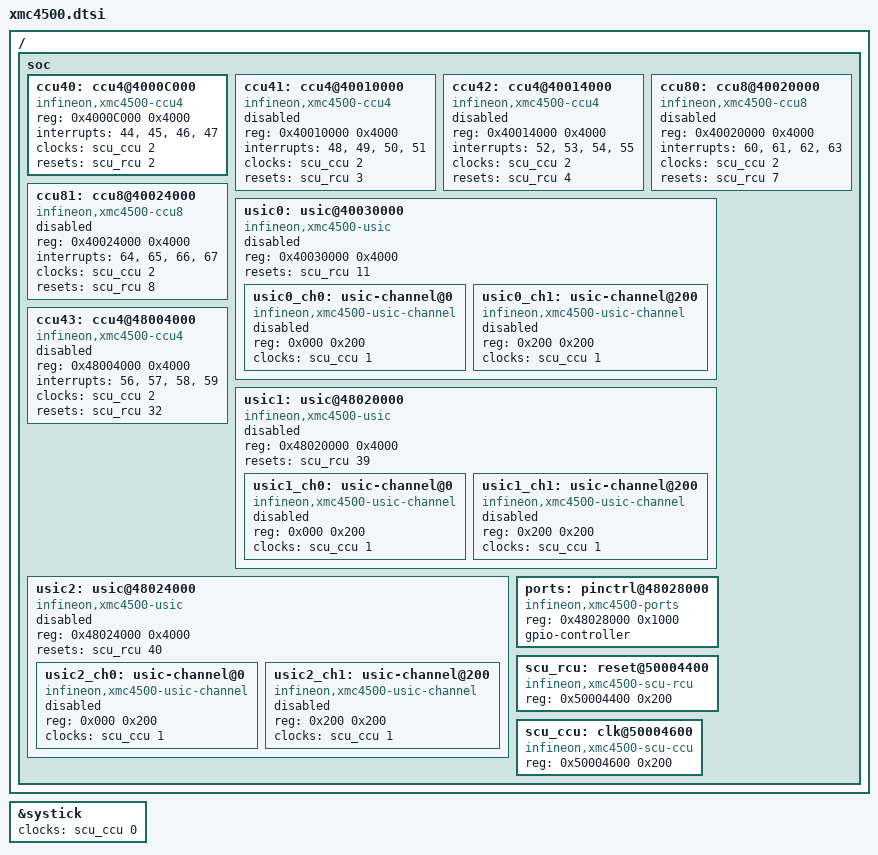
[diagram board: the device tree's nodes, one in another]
/*
 * Device tree for Infineon XMC4500
 *
 * Copyright 2015-2016 Andreas Färber
 *
 * This file is dual-licensed: you can use it either under the terms
 * of the GPL or the X11 license, at your option. Note that this dual
 * licensing only applies to this file, and not this project as a
 * whole.
 *
 *  a) This file is free software; you can redistribute it and/or
 *     modify it under the terms of the GNU General Public License as
 *     published by the Free Software Foundation; either version 2 of the
 *     License, or (at your option) any later version.
 *
 *     This file is distributed in the hope that it will be useful,
 *     but WITHOUT ANY WARRANTY; without even the implied warranty of
 *     MERCHANTABILITY or FITNESS FOR A PARTICULAR PURPOSE.  See the
 *     GNU General Public License for more details.
 *
 * Or, alternatively,
 *
 *  b) Permission is hereby granted, free of charge, to any person
 *     obtaining a copy of this software and associated documentation
 *     files (the "Software"), to deal in the Software without
 *     restriction, including without limitation the rights to use,
 *     copy, modify, merge, publish, distribute, sublicense, and/or
 *     sell copies of the Software, and to permit persons to whom the
 *     Software is furnished to do so, subject to the following
 *     conditions:
 *
 *     The above copyright notice and this permission notice shall be
 *     included in all copies or substantial portions of the Software.
 *
 *     THE SOFTWARE IS PROVIDED "AS IS", WITHOUT WARRANTY OF ANY KIND,
 *     EXPRESS OR IMPLIED, INCLUDING BUT NOT LIMITED TO THE WARRANTIES
 *     OF MERCHANTABILITY, FITNESS FOR A PARTICULAR PURPOSE AND
 *     NONINFRINGEMENT. IN NO EVENT SHALL THE AUTHORS OR COPYRIGHT
 *     HOLDERS BE LIABLE FOR ANY CLAIM, DAMAGES OR OTHER LIABILITY,
 *     WHETHER IN AN ACTION OF CONTRACT, TORT OR OTHERWISE, ARISING
 *     FROM, OUT OF OR IN CONNECTION WITH THE SOFTWARE OR THE USE OR
 *     OTHER DEALINGS IN THE SOFTWARE.
 */

#include "armv7-m.dtsi"

/ {
	soc {
		ccu40: ccu4@4000C000 {
			compatible = "infineon,xmc4500-ccu4";
			reg = <0x4000C000 0x4000>;
			interrupts = <44>, <45>, <46>, <47>;
			clocks = <&scu_ccu 2>;
			clock-names = "mclk";
			resets = <&scu_rcu 2>;
		};

		ccu41: ccu4@40010000 {
			compatible = "infineon,xmc4500-ccu4";
			reg = <0x40010000 0x4000>;
			interrupts = <48>, <49>, <50>, <51>;
			clocks = <&scu_ccu 2>;
			clock-names = "mclk";
			resets = <&scu_rcu 3>;
			status = "disabled";
		};

		ccu42: ccu4@40014000 {
			compatible = "infineon,xmc4500-ccu4";
			reg = <0x40014000 0x4000>;
			interrupts = <52>, <53>, <54>, <55>;
			clocks = <&scu_ccu 2>;
			clock-names = "mclk";
			resets = <&scu_rcu 4>;
			status = "disabled";
		};

		ccu80: ccu8@40020000 {
			compatible = "infineon,xmc4500-ccu8";
			reg = <0x40020000 0x4000>;
			interrupts = <60>, <61>, <62>, <63>;
			clocks = <&scu_ccu 2>;
			resets = <&scu_rcu 7>;
			status = "disabled";
		};

		ccu81: ccu8@40024000 {
			compatible = "infineon,xmc4500-ccu8";
			reg = <0x40024000 0x4000>;
			interrupts = <64>, <65>, <66>, <67>;
			clocks = <&scu_ccu 2>;
			resets = <&scu_rcu 8>;
			status = "disabled";
		};

		usic0: usic@40030000 {
			compatible = "infineon,xmc4500-usic";
			reg = <0x40030000 0x4000>;
			resets = <&scu_rcu 11>;
			#address-cells = <1>;
			#size-cells = <1>;
			ranges = <0x0 0x40030000 0x4000>;
			status = "disabled";

			usic0_ch0: usic-channel@0 {
				compatible = "infineon,xmc4500-usic-channel";
				reg = <0x000 0x200>;
				clocks = <&scu_ccu 1>;
				status = "disabled";
			};

			usic0_ch1: usic-channel@200 {
				compatible = "infineon,xmc4500-usic-channel";
				reg = <0x200 0x200>;
				clocks = <&scu_ccu 1>;
				status = "disabled";
			};
		};

		ccu43: ccu4@48004000 {
			compatible = "infineon,xmc4500-ccu4";
			reg = <0x48004000 0x4000>;
			interrupts = <56>, <57>, <58>, <59>;
			clocks = <&scu_ccu 2>;
			clock-names = "mclk";
			resets = <&scu_rcu 32>;
			status = "disabled";
		};

		usic1: usic@48020000 {
			compatible = "infineon,xmc4500-usic";
			reg = <0x48020000 0x4000>;
			resets = <&scu_rcu 39>;
			#address-cells = <1>;
			#size-cells = <1>;
			ranges = <0x0 0x48020000 0x4000>;
			status = "disabled";

			usic1_ch0: usic-channel@0 {
				compatible = "infineon,xmc4500-usic-channel";
				reg = <0x000 0x200>;
				clocks = <&scu_ccu 1>;
				status = "disabled";
			};

			usic1_ch1: usic-channel@200 {
				compatible = "infineon,xmc4500-usic-channel";
				reg = <0x200 0x200>;
				clocks = <&scu_ccu 1>;
				status = "disabled";
			};
		};

		usic2: usic@48024000 {
			compatible = "infineon,xmc4500-usic";
			reg = <0x48024000 0x4000>;
			resets = <&scu_rcu 40>;
			#address-cells = <1>;
			#size-cells = <1>;
			ranges = <0x0 0x48024000 0x4000>;
			status = "disabled";

			usic2_ch0: usic-channel@0 {
				compatible = "infineon,xmc4500-usic-channel";
				reg = <0x000 0x200>;
				clocks = <&scu_ccu 1>;
				status = "disabled";
			};

			usic2_ch1: usic-channel@200 {
				compatible = "infineon,xmc4500-usic-channel";
				reg = <0x200 0x200>;
				clocks = <&scu_ccu 1>;
				status = "disabled";
			};
		};

		ports: pinctrl@48028000 {
			compatible = "infineon,xmc4500-ports";
			reg = <0x48028000 0x1000>;
			gpio-controller;
			#gpio-cells = <3>;
		};

		scu_rcu: reset@50004400 {
			compatible = "infineon,xmc4500-scu-rcu";
			reg = <0x50004400 0x200>;
			#reset-cells = <1>;
		};

		scu_ccu: clk@50004600 {
			compatible = "infineon,xmc4500-scu-ccu";
			reg = <0x50004600 0x200>;
			#clock-cells = <1>;
		};
	};
};

&systick {
	status = "okay";
	clocks = <&scu_ccu 0>;
};
